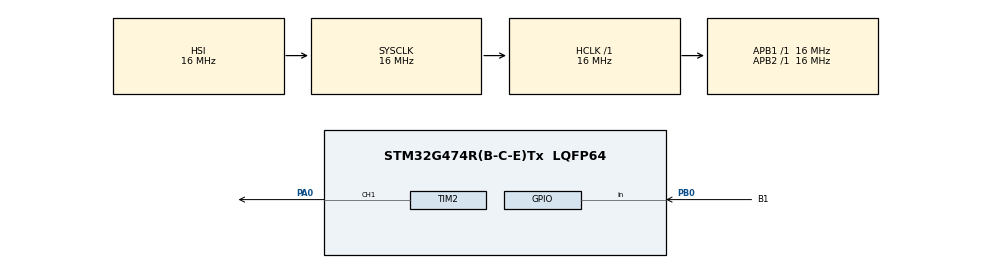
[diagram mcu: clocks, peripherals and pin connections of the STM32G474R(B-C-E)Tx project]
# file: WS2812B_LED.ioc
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Dma.Request0=TIM2_CH1
Dma.TIM2_CH1.0.Direction=DMA_MEMORY_TO_PERIPH
Dma.TIM2_CH1.0.EventEnable=DISABLE
Dma.TIM2_CH1.0.Instance=DMA1_Channel1
Dma.TIM2_CH1.0.MemDataAlignment=DMA_MDATAALIGN_WORD
Dma.TIM2_CH1.0.MemInc=DMA_MINC_ENABLE
Dma.TIM2_CH1.0.Mode=DMA_NORMAL
Dma.TIM2_CH1.0.PeriphDataAlignment=DMA_PDATAALIGN_WORD
Dma.TIM2_CH1.0.PeriphInc=DMA_PINC_DISABLE
Dma.TIM2_CH1.0.Polarity=HAL_DMAMUX_REQ_GEN_RISING
Dma.TIM2_CH1.0.Priority=DMA_PRIORITY_LOW
Dma.TIM2_CH1.0.RequestNumber=1
Dma.TIM2_CH1.0.SignalID=NONE
Dma.TIM2_CH1.0.SyncEnable=DISABLE
Dma.TIM2_CH1.0.SyncPolarity=HAL_DMAMUX_SYNC_NO_EVENT
Dma.TIM2_CH1.0.SyncRequestNumber=1
Dma.TIM2_CH1.0.SyncSignalID=NONE
Mcu.Family=STM32G4
Mcu.Name=STM32G474R(B-C-E)Tx
Mcu.Package=LQFP64
NVIC.DMA1_Channel1_IRQn=true\:0\:0\:false\:false\:true\:false\:true\:true
NVIC.PriorityGroup=NVIC_PRIORITYGROUP_4
NVIC.TIM2_IRQn=true\:0\:0\:false\:false\:true\:true\:true\:true
PA0.Signal=S_TIM2_CH1
PB0.GPIO_Label=B1
PB0.GPIO_PuPd=GPIO_PULLUP
PB0.Signal=GPIO_Input
ProjectManager.HeapSize=0x200
ProjectManager.StackSize=0x400
ProjectManager.TargetToolchain=STM32CubeIDE
RCC.ADC12Freq_Value=16000000
RCC.ADC345Freq_Value=16000000
RCC.AHBFreq_Value=16000000
RCC.APB1Freq_Value=16000000
RCC.APB1TimFreq_Value=16000000
RCC.APB2Freq_Value=16000000
RCC.APB2TimFreq_Value=16000000
RCC.CortexFreq_Value=16000000
RCC.EXTERNAL_CLOCK_VALUE=12288000
RCC.HCLKFreq_Value=16000000
RCC.HSE_VALUE=8000000
RCC.HSI48_VALUE=48000000
RCC.HSI_VALUE=16000000
RCC.LSE_VALUE=32768
RCC.SYSCLKFreq_VALUE=16000000
RCC.USBFreq_Value=64000000
RCC.VCOOutputFreq_Value=128000000
SH.S_TIM2_CH1.0=TIM2_CH1,PWM Generation1 CH1
TIM2.Channel-PWM\ Generation1\ CH1=TIM_CHANNEL_1
TIM2.PeriodNoDither=19
VP_SYS_VS_DBSignals.Mode=DisableDeadBatterySignals
board=custom

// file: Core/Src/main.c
/* USER CODE BEGIN Header */
/**
 ******************************************************************************
 * @file           : main.c
 * @brief          : Main program body
 ******************************************************************************
 * @attention
 *
 * Copyright (c) 2024 STMicroelectronics.
 * All rights reserved.
 *
 * This software is licensed under terms that can be found in the LICENSE file
 * in the root directory of this software component.
 * If no LICENSE file comes with this software, it is provided AS-IS.
 *
 ******************************************************************************
 */
/* USER CODE END Header */
#include "main.h"

/* USER CODE BEGIN Includes */
#include "LED.h"
/* USER CODE END Includes */

/* USER CODE BEGIN PD */
#define LED_COUNT 1
/* USER CODE END PD */

TIM_HandleTypeDef htim2;
DMA_HandleTypeDef hdma_tim2_ch1;

/* USER CODE BEGIN PV */
uint32_t red_tick = 0;
uint32_t green_tick = 0;
uint32_t blue_tick = 0;

uint8_t red_state = 0;
uint8_t blue_state = 0;
uint8_t blue_presed = 0;
uint8_t blue_count = 0;

struct LED_DataBuffer colors[LED_COUNT + 2];
/* USER CODE END PV */

void SystemClock_Config(void);
static void MX_GPIO_Init(void);
static void MX_DMA_Init(void);
static void MX_TIM2_Init(void);

int main(void)
{

  /* MCU Configuration--------------------------------------------------------*/

  /* Reset of all peripherals, Initializes the Flash interface and the Systick. */
  HAL_Init();

  /* Configure the system clock */
  SystemClock_Config();

  /* Initialize all configured peripherals */
  MX_GPIO_Init();
  MX_DMA_Init();
  MX_TIM2_Init();
  /* USER CODE BEGIN 2 */
  colors[LED_COUNT] = LED_getResetCode();
  colors[LED_COUNT + 1] = LED_getResetCode();
  /* USER CODE END 2 */

  /* Infinite loop */
  /* USER CODE BEGIN WHILE */
	while (1)
	{
		uint32_t tick = HAL_GetTick();

		uint8_t R, G, B;

		// Toggling red color every 1.5s
		if (tick - red_tick >= 1500)
		{
			if (red_state == 0)
			{
				R = 255;
				red_state = 1;
			}
			else
			{
				R = 0;
				red_state = 0;
			}

			red_tick = tick;
		}
		// end red

		// Generating sawtooth signal for green color
		uint32_t green_time = tick - green_tick;
		if (green_time >= 3000)
		{
			green_tick = tick;
		}

		G = green_time * 255 / 3000;
		// end green

		// Registering button press, and blocking further registration
		if (blue_presed == 0 && HAL_GPIO_ReadPin(B1_GPIO_Port, B1_Pin) == GPIO_PIN_RESET)
		{
			blue_presed = 1;
		}

		// Toggling blue color on and off 3 times
		if (blue_presed)
		{
			if (tick - blue_tick >= 500)
			{
				blue_tick = tick;
				if (blue_state == 0)
				{
					B = 255;
					blue_state = 1;
				}
				else
				{
					B = 0;
					blue_state = 0;
				}

				blue_count++;

				// Unblocking button registration and reseting blue led state
				if (blue_count >= 6)
				{
					blue_count = 0;
					blue_presed = 0;
				}
			}
		}
		// end blue

		// Generating buffer with proper PDW widths
		colors[0] = LED_getColorBuffer(R, G, B);

		HAL_TIM_PWM_Start_DMA(&htim2, TIM_CHANNEL_1, (uint32_t*)&colors, 24 * (LED_COUNT + 2));

		HAL_Delay(1);
    /* USER CODE END WHILE */

	}
}

void SystemClock_Config(void)
{
  RCC_OscInitTypeDef RCC_OscInitStruct = {0};
  RCC_ClkInitTypeDef RCC_ClkInitStruct = {0};

  /** Configure the main internal regulator output voltage
  */
  HAL_PWREx_ControlVoltageScaling(PWR_REGULATOR_VOLTAGE_SCALE1);

  /** Initializes the RCC Oscillators according to the specified parameters
  * in the RCC_OscInitTypeDef structure.
  */
  RCC_OscInitStruct.OscillatorType = RCC_OSCILLATORTYPE_HSI;
  RCC_OscInitStruct.HSIState = RCC_HSI_ON;
  RCC_OscInitStruct.HSICalibrationValue = RCC_HSICALIBRATION_DEFAULT;
  RCC_OscInitStruct.PLL.PLLState = RCC_PLL_NONE;
  if (HAL_RCC_OscConfig(&RCC_OscInitStruct) != HAL_OK)
  {
    Error_Handler();
  }

  /** Initializes the CPU, AHB and APB buses clocks
  */
  RCC_ClkInitStruct.ClockType = RCC_CLOCKTYPE_HCLK|RCC_CLOCKTYPE_SYSCLK
                              |RCC_CLOCKTYPE_PCLK1|RCC_CLOCKTYPE_PCLK2;
  RCC_ClkInitStruct.SYSCLKSource = RCC_SYSCLKSOURCE_HSI;
  RCC_ClkInitStruct.AHBCLKDivider = RCC_SYSCLK_DIV1;
  RCC_ClkInitStruct.APB1CLKDivider = RCC_HCLK_DIV1;
  RCC_ClkInitStruct.APB2CLKDivider = RCC_HCLK_DIV1;

  if (HAL_RCC_ClockConfig(&RCC_ClkInitStruct, FLASH_LATENCY_0) != HAL_OK)
  {
    Error_Handler();
  }
}

static void MX_TIM2_Init(void)
{

  TIM_MasterConfigTypeDef sMasterConfig = {0};
  TIM_OC_InitTypeDef sConfigOC = {0};

  htim2.Instance = TIM2;
  htim2.Init.Prescaler = 0;
  htim2.Init.CounterMode = TIM_COUNTERMODE_UP;
  htim2.Init.Period = 19;
  htim2.Init.ClockDivision = TIM_CLOCKDIVISION_DIV1;
  htim2.Init.AutoReloadPreload = TIM_AUTORELOAD_PRELOAD_DISABLE;
  if (HAL_TIM_PWM_Init(&htim2) != HAL_OK)
  {
    Error_Handler();
  }
  sMasterConfig.MasterOutputTrigger = TIM_TRGO_RESET;
  sMasterConfig.MasterSlaveMode = TIM_MASTERSLAVEMODE_DISABLE;
  if (HAL_TIMEx_MasterConfigSynchronization(&htim2, &sMasterConfig) != HAL_OK)
  {
    Error_Handler();
  }
  sConfigOC.OCMode = TIM_OCMODE_PWM1;
  sConfigOC.Pulse = 0;
  sConfigOC.OCPolarity = TIM_OCPOLARITY_HIGH;
  sConfigOC.OCFastMode = TIM_OCFAST_DISABLE;
  if (HAL_TIM_PWM_ConfigChannel(&htim2, &sConfigOC, TIM_CHANNEL_1) != HAL_OK)
  {
    Error_Handler();
  }
  HAL_TIM_MspPostInit(&htim2);

}

static void MX_DMA_Init(void)
{

  /* DMA controller clock enable */
  __HAL_RCC_DMAMUX1_CLK_ENABLE();
  __HAL_RCC_DMA1_CLK_ENABLE();

  /* DMA interrupt init */
  /* DMA1_Channel1_IRQn interrupt configuration */
  HAL_NVIC_SetPriority(DMA1_Channel1_IRQn, 0, 0);
  HAL_NVIC_EnableIRQ(DMA1_Channel1_IRQn);

}

static void MX_GPIO_Init(void)
{
  GPIO_InitTypeDef GPIO_InitStruct = {0};

  /* GPIO Ports Clock Enable */
  __HAL_RCC_GPIOA_CLK_ENABLE();
  __HAL_RCC_GPIOB_CLK_ENABLE();

  /*Configure GPIO pin : B1_Pin */
  GPIO_InitStruct.Pin = B1_Pin;
  GPIO_InitStruct.Mode = GPIO_MODE_INPUT;
  GPIO_InitStruct.Pull = GPIO_PULLUP;
  HAL_GPIO_Init(B1_GPIO_Port, &GPIO_InitStruct);

}

void Error_Handler(void)
{
	__disable_irq();
	while (1)
	{
	}
}
